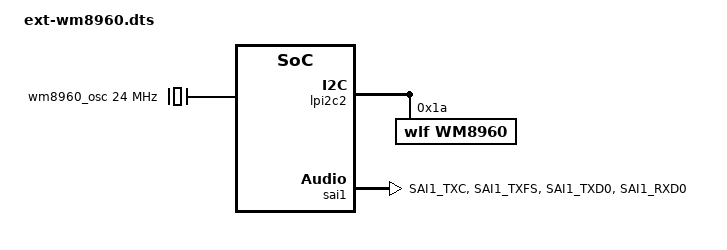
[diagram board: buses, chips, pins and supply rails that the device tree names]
/*
 * Copyright 2023 AVNET
 *
 * This program is free software; you can redistribute it and/or
 * modify it under the terms of the GNU General Public License
 * as published by the Free Software Foundation; either version 2
 * of the License, or (at your option) any later version.
 *
 * This program is distributed in the hope that it will be useful,
 * but WITHOUT ANY WARRANTY; without even the implied warranty of
 * MERCHANTABILITY or FITNESS FOR A PARTICULAR PURPOSE.  See the
 * GNU General Public License for more details.
 */

/dts-v1/;
/plugin/;

#include <dt-bindings/clock/imx93-clock.h>
#include "../imx93-pinfunc.h"


&lpi2c2 {
	status = "okay";

	wm8960: wm8960@1a {
		#sound-dai-cells = <0>;
		compatible = "wlf,wm8960";
		reg = <0x1a>;
		clocks = <&wm8960_osc>;
		clock-names = "mclk";
		wlf,shared-lrclk;
	};
};

&sai1 {
	#sound-dai-cells = <0>;
	pinctrl-names = "default";
	pinctrl-0 = <&pinctrl_sai1>;
	assigned-clocks = <&clk IMX93_CLK_SAI1>;
	assigned-clock-parents = <&clk IMX93_CLK_AUDIO_PLL>;
	assigned-clock-rates = <24576000>;
	status = "okay";
};

&iomuxc {
	pinctrl_sai1: sai1grp {
		fsl,pins = <
			MX93_PAD_SAI1_TXC__SAI1_TX_BCLK			0x31e
			MX93_PAD_SAI1_TXFS__SAI1_TX_SYNC		0x31e
			MX93_PAD_SAI1_TXD0__SAI1_TX_DATA00		0x31e
			MX93_PAD_SAI1_RXD0__SAI1_RX_DATA00		0x31e
		>;
	};
};

/ {
	fragment@3 {
		target-path = "/";
		__overlay__ {
			sound-wm8960 {
				compatible = "simple-audio-card";
				simple-audio-card,name = "wm8960-sound-audio";
				simple-audio-card,bitclock-master = <&dailink_master>;
				simple-audio-card,frame-master = <&dailink_master>;
				simple-audio-card,format = "i2s";
				status = "okay";
				simple-audio-card,widgets =
						"Microphone", "Mic Jack",
						"Line", "Line In",
						"Line", "Line Out",
						"Speaker", "Speaker",
						"Headphone", "Headphone Jack";
				simple-audio-card,routing =
						"Headphone Jack", "HP_L",
						"Headphone Jack", "HP_R",
						"Speaker", "SPK_LP",
						"Speaker", "SPK_LN",
						"Speaker", "SPK_RP",
						"Speaker", "SPK_RN",
						"LINPUT1", "Mic Jack",
						"LINPUT3", "Mic Jack",
						"RINPUT1", "Mic Jack",
						"RINPUT2", "Mic Jack",
						"Mic Jack", "MICB";

				simple-audio-card,cpu {
					sound-dai = <&sai1>;
				};

				dailink_master: simple-audio-card,codec {
					sound-dai = <&wm8960>;
					clocks = <&wm8960_osc>;
				};
			};

			wm8960_osc: wm8960_mclk {
					compatible = "fixed-clock";
					#clock-cells = <0>;
					clock-frequency = <24000000>;
					clock-output-names = "wm8960-mclk";
			};
		};
	};
};
